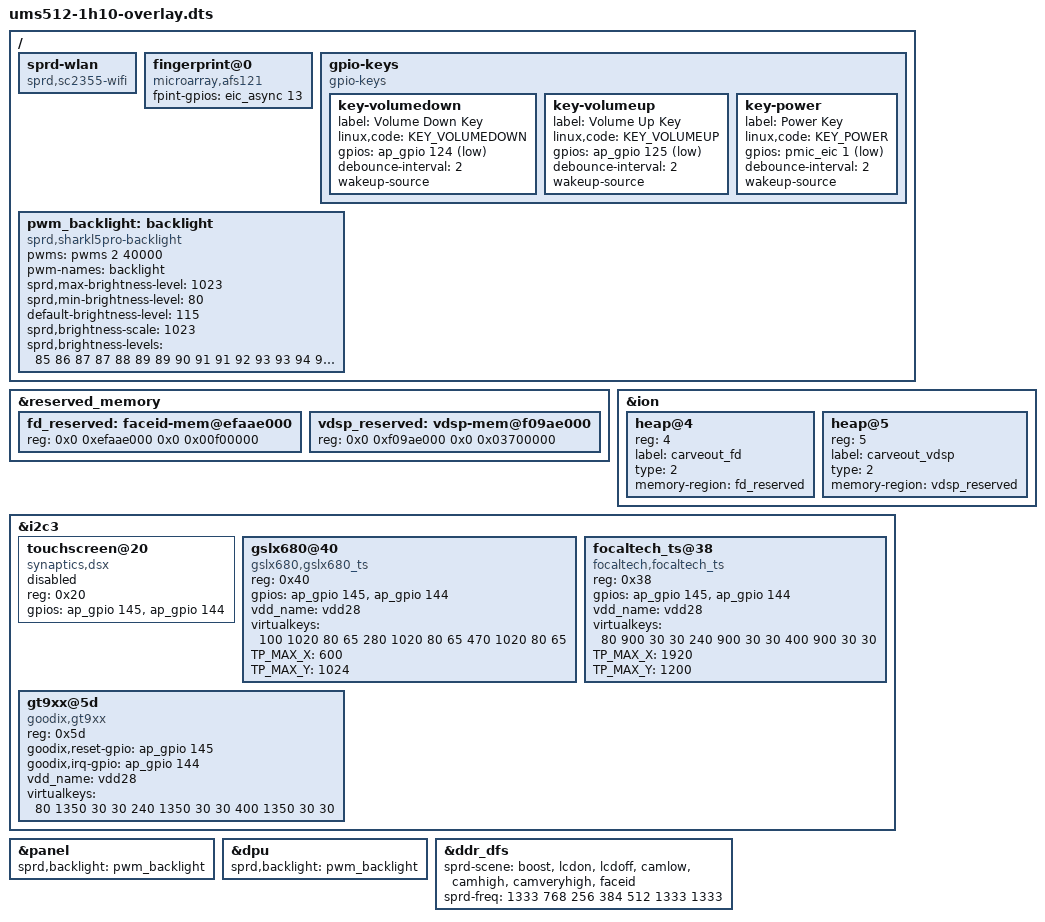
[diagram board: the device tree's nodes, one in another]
/dts-v1/;
/plugin/;

#include <dt-bindings/input/input.h>
#include <dt-bindings/gpio/gpio.h>

/ {
	fragment {
		target-path = "/";
		__overlay__ {
			sprd-wlan {
				compatible = "sprd,sc2355-wifi";
			};

			fingerprint@0 {
				compatible = "microarray,afs121";
				fpint-gpios = <&eic_async 13 0>;
			};

			gpio-keys {
				compatible = "gpio-keys";

				key-volumedown {
					label = "Volume Down Key";
					linux,code = <KEY_VOLUMEDOWN>;
					gpios = <&ap_gpio 124 GPIO_ACTIVE_LOW>;
					debounce-interval = <2>;
					wakeup-source;
				};

				key-volumeup {
					label = "Volume Up Key";
					linux,code = <KEY_VOLUMEUP>;
					gpios = <&ap_gpio 125 GPIO_ACTIVE_LOW>;
					debounce-interval = <2>;
					wakeup-source;
				};

				key-power {
					label = "Power Key";
					linux,code = <KEY_POWER>;
					gpios = <&pmic_eic 1 GPIO_ACTIVE_LOW>;
					debounce-interval = <2>;
					wakeup-source;
				};
			};

			pwm_backlight: backlight {
				compatible = "sprd,sharkl5pro-backlight";
				pwms = <&pwms 2 40000>;
				pwm-names = "backlight";
				sprd,max-brightness-level = <1023>;
				sprd,min-brightness-level = <80>;
				default-brightness-level = <115>;
				sprd,brightness-scale = <1023>;
				sprd,brightness-levels = <
          85  86  87  87  88  89  89  90  91  91
          92  93  93  94  95  95  96  97  97  98
          99  99 100 101 101 102 103 103 104 105
         105 106 107 107 108 109 109 110 111 111
         112 113 113 114 115 115 116 117 117 118
         119 119 120 121 121 122 123 123 124 125
         125 126 127 127 128 129 129 130 131 131
         132 133 133 134 135 135 136 137 137 138
         139 139 140 141 141 142 143 143 144 145
         145 146 147 147 148 149 149 150 151 151
         152 153 153 154 155 155 156 157 157 158
         159 159 160 161 161 162 163 163 164 165
         165 166 167 167 168 169 169 170 171 171
         172 173 173 174 175 175 176 177 177 178
         179 179 180 181 181 182 183 183 184 185
         185 186 187 187 188 189 189 190 191 191
         192 193 193 194 195 195 196 197 197 198
         199 199 200 201 201 202 203 203 204 205
         205 206 207 207 208 209 209 210 211 211
         212 213 213 214 215 215 216 217 217 218
         219 219 220 221 221 222 223 223 224 225
         225 226 227 227 228 229 229 230 231 231
         232 233 233 234 235 235 236 237 237 238
         239 239 240 241 241 242 243 243 244 245
         245 246 247 247 248 249 249 250 251 251
         252 253 253 254 255 255
         >;
			};
		};
	};

};

&reserved_memory {

	fd_reserved: faceid-mem@efaae000 {
		reg = <0x0 0xefaae000 0x0 0x00f00000>;
	};

	vdsp_reserved: vdsp-mem@f09ae000 {
		reg = <0x0 0xf09ae000 0x0 0x03700000>;
	};
/*
	gpu_reserved: gpu-mem@fb8ae000 {
		reg = <0x0 0xfb8ae000 0x0 0x01e5a000>;
	};
*/
};

&ion {
	heap@4 {
		reg = <4>;
		label = "carveout_fd";
		type = <2>;
		memory-region = <&fd_reserved>;
	};

	heap@5 {
		reg = <5>;
		label = "carveout_vdsp";
		type = <2>;
		memory-region = <&vdsp_reserved>;
	};
};

&i2c3 {
	status = "okay";

	touchscreen@20 {
		status = "disabled";
		compatible = "synaptics,dsx";
		reg = <0x20>;
		gpios = <&ap_gpio 145 GPIO_ACTIVE_HIGH
			&ap_gpio 144 GPIO_ACTIVE_HIGH>;
	};
	
	gslx680@40{
		compatible = "gslx680,gslx680_ts";
		reg = <0x40>;
		gpios = <&ap_gpio 145 GPIO_ACTIVE_HIGH
						 &ap_gpio 144 GPIO_ACTIVE_HIGH>;
		vdd_name = "vdd28";
		virtualkeys = <100 1020 80 65
									 280 1020 80 65
									 470 1020 80 65>;
		TP_MAX_X = <600>;
		TP_MAX_Y = <1024>;
	};	

       focaltech_ts@38{
           status = "okay";
           compatible = "focaltech,focaltech_ts";
           reg = <0x38>;
           gpios = <&ap_gpio 145 0
                    &ap_gpio 144 0>;
           vdd_name = "vdd28";
           virtualkeys = <80 900 30 30
                          240 900 30 30
                          400 900 30 30>;
           TP_MAX_X = <1920>;
           TP_MAX_Y = <1200>;
       };   
       gt9xx@5d{
	       status = "okay";
	       compatible = "goodix,gt9xx";
	       reg = <0x5d>;
	       //gpios = <&ap_gpio 145 0
	       //       &ap_gpio 144 0>;
	       goodix,reset-gpio = <&ap_gpio 145 GPIO_ACTIVE_HIGH>;
	       goodix,irq-gpio = <&ap_gpio 144 GPIO_ACTIVE_HIGH>;
	       vdd_name = "vdd28";
	       virtualkeys = <80 1350 30 30
		       240 1350 30 30
		       400 1350 30 30>;
       };

};

&panel {
	sprd,backlight = <&pwm_backlight>;
};

&dpu {
	sprd,backlight = <&pwm_backlight>;
};

&ddr_dfs {
	sprd-scene = "boost", "lcdon", "lcdoff", "camlow",
		"camhigh", "camveryhigh", "faceid";
	sprd-freq = <1333 768 256 384 512 1333 1333>;
};
